# WKUP_SEC_MMR_WKUP_SEC_MMR_CFG2_45920000h register map
Vendor: Texas Instruments
Peripheral module from a debugger description file (folder AM275x).
Registers are 32-bit, read-write, reset 0xAA00 unless marked. A register's access mark holds for its fields unless they carry their own. Offsets are as the file gives them; lines under a group give offsets from that group; [hi:lo] are bit positions; {n}, {i} and the like mark numbered series; 'fields as' and 'values as' point back to an identical list; <NAME> marks a mode.

## WKUP_SEC_MMR_CFG2
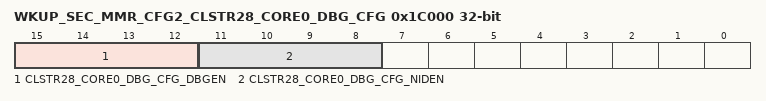
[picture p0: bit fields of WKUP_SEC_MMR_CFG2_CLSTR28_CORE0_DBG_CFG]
0x1C000 WKUP_SEC_MMR_CFG2_CLSTR28_CORE0_DBG_CFG — Configures debug operation for R5FSS28 Core0
  [15:12] CLSTR28_CORE0_DBG_CFG_DBGEN — Core0 Invasive debug enable. This is a fault tolerant bitfield that must be set 4'hA to enable 4'b1010 - Enabled others - Disabled Reset Source: sys_por_rst_n
  [11:8] CLSTR28_CORE0_DBG_CFG_NIDEN — Core0 Non-invasive debug enable. This is a fault tolerant bitfield that must be set 4'hA to enable 4'b1010 - Enabled others - Disabled Reset Source: sys_por_rst_n
0x1C040 WKUP_SEC_MMR_CFG2_CLSTR28_CORE1_DBG_CFG ro reset 0x0 — Configures debug operation for R5FSS28 Core1
  [31:0] CLSTR28_CORE1_DBG_CFG_RESERVED — Not used for Device Manager R5F
